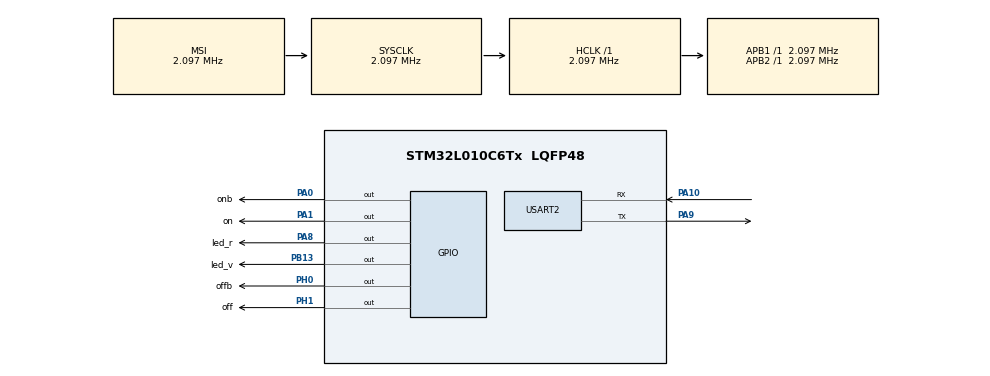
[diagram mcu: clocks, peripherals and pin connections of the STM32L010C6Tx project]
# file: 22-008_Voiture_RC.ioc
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Mcu.Family=STM32L0
Mcu.Name=STM32L010C6Tx
Mcu.Package=LQFP48
PA0.GPIO_Label=onb
PA0.GPIO_PuPd=GPIO_PULLDOWN
PA0.Signal=GPIO_Output
PA1.GPIO_Label=on
PA1.GPIO_PuPd=GPIO_PULLDOWN
PA1.Signal=GPIO_Output
PA10.Mode=Asynchronous
PA10.Signal=USART2_RX
PA8.GPIO_Label=led_r
PA8.PinState=GPIO_PIN_RESET
PA8.Signal=GPIO_Output
PA9.Mode=Asynchronous
PA9.Signal=USART2_TX
PB13.GPIO_Label=led_v
PB13.PinState=GPIO_PIN_RESET
PB13.Signal=GPIO_Output
PH0-OSC_IN.GPIO_Label=offb
PH0-OSC_IN.GPIO_PuPd=GPIO_PULLUP
PH0-OSC_IN.Signal=GPIO_Output
PH1-OSC_OUT.GPIO_Label=off
PH1-OSC_OUT.GPIO_PuPd=GPIO_PULLDOWN
PH1-OSC_OUT.Signal=GPIO_Output
ProjectManager.HeapSize=0x200
ProjectManager.StackSize=0x400
ProjectManager.TargetToolchain=STM32CubeIDE
RCC.AHBFreq_Value=2097000
RCC.APB1Freq_Value=2097000
RCC.APB1TimFreq_Value=2097000
RCC.APB2Freq_Value=2097000
RCC.APB2TimFreq_Value=2097000
RCC.HSE_VALUE=8000000
RCC.HSI16_VALUE=16000000
RCC.HSI_VALUE=16000000
RCC.LSE_VALUE=32768
RCC.MSI_VALUE=2097000
RCC.SYSCLKFreq_VALUE=2097000
RCC.VCOOutputFreq_Value=48000000
USART2.VirtualMode=VM_ASYNC
board=custom

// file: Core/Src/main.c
/* USER CODE BEGIN Header */
/**
  ******************************************************************************
  * @file           : main.c
  * @brief          : Main program body
  ******************************************************************************
  * @attention
  *
  * Copyright (c) 2023 STMicroelectronics.
  * All rights reserved.
  *
  * This software is licensed under terms that can be found in the LICENSE file
  * in the root directory of this software component.
  * If no LICENSE file comes with this software, it is provided AS-IS.
  *
  ******************************************************************************
  */
/* USER CODE END Header */
#include "main.h"

/* USER CODE BEGIN Includes */
#include "hal.h"
/* USER CODE END Includes */

UART_HandleTypeDef huart2;

void SystemClock_Config(void);
static void MX_GPIO_Init(void);
static void MX_USART2_UART_Init(void);

int main(void)
{

  /* MCU Configuration--------------------------------------------------------*/

  /* Reset of all peripherals, Initializes the Flash interface and the Systick. */
  HAL_Init();

  /* Configure the system clock */
  SystemClock_Config();

  /* Initialize all configured peripherals */
  MX_GPIO_Init();
  MX_USART2_UART_Init();

  /* Infinite loop */
  /* USER CODE BEGIN WHILE */
  uint32_t time_U32 = HAL_millis_U32();
  const uint32_t timeout_ms_U32 = 500;
  bool flag_led_B = false;
  while (1)
  {
	  /*if (HAL_millis_U32()-time_U32>timeout_ms_U32)
	  {
		  HAL_setLed(LED_ROUGE_EN, flag_led_B);
		  flag_led_B = 1-flag_led_B;
		  time_U32 = HAL_millis_U32();
	  }*/
	  HAL_GPIO_WritePin(GPIOH, offb_Pin, GPIO_PIN_SET);
	  HAL_GPIO_WritePin(GPIOH, off_Pin, GPIO_PIN_SET);
	  HAL_GPIO_WritePin(GPIOA, onb_Pin, GPIO_PIN_RESET);
	  HAL_GPIO_WritePin(GPIOA, on_Pin, GPIO_PIN_RESET);

    /* USER CODE END WHILE */

  }
}

void SystemClock_Config(void)
{
  RCC_OscInitTypeDef RCC_OscInitStruct = {0};
  RCC_ClkInitTypeDef RCC_ClkInitStruct = {0};
  RCC_PeriphCLKInitTypeDef PeriphClkInit = {0};

  /** Configure the main internal regulator output voltage
  */
  __HAL_PWR_VOLTAGESCALING_CONFIG(PWR_REGULATOR_VOLTAGE_SCALE1);

  /** Initializes the RCC Oscillators according to the specified parameters
  * in the RCC_OscInitTypeDef structure.
  */
  RCC_OscInitStruct.OscillatorType = RCC_OSCILLATORTYPE_MSI;
  RCC_OscInitStruct.MSIState = RCC_MSI_ON;
  RCC_OscInitStruct.MSICalibrationValue = 0;
  RCC_OscInitStruct.MSIClockRange = RCC_MSIRANGE_5;
  RCC_OscInitStruct.PLL.PLLState = RCC_PLL_NONE;
  if (HAL_RCC_OscConfig(&RCC_OscInitStruct) != HAL_OK)
  {
    Error_Handler();
  }

  /** Initializes the CPU, AHB and APB buses clocks
  */
  RCC_ClkInitStruct.ClockType = RCC_CLOCKTYPE_HCLK|RCC_CLOCKTYPE_SYSCLK
                              |RCC_CLOCKTYPE_PCLK1|RCC_CLOCKTYPE_PCLK2;
  RCC_ClkInitStruct.SYSCLKSource = RCC_SYSCLKSOURCE_MSI;
  RCC_ClkInitStruct.AHBCLKDivider = RCC_SYSCLK_DIV1;
  RCC_ClkInitStruct.APB1CLKDivider = RCC_HCLK_DIV1;
  RCC_ClkInitStruct.APB2CLKDivider = RCC_HCLK_DIV1;

  if (HAL_RCC_ClockConfig(&RCC_ClkInitStruct, FLASH_LATENCY_0) != HAL_OK)
  {
    Error_Handler();
  }
  PeriphClkInit.PeriphClockSelection = RCC_PERIPHCLK_USART2;
  PeriphClkInit.Usart2ClockSelection = RCC_USART2CLKSOURCE_PCLK1;
  if (HAL_RCCEx_PeriphCLKConfig(&PeriphClkInit) != HAL_OK)
  {
    Error_Handler();
  }
}

static void MX_USART2_UART_Init(void)
{

  huart2.Instance = USART2;
  huart2.Init.BaudRate = 115200;
  huart2.Init.WordLength = UART_WORDLENGTH_8B;
  huart2.Init.StopBits = UART_STOPBITS_1;
  huart2.Init.Parity = UART_PARITY_NONE;
  huart2.Init.Mode = UART_MODE_TX_RX;
  huart2.Init.HwFlowCtl = UART_HWCONTROL_NONE;
  huart2.Init.OverSampling = UART_OVERSAMPLING_16;
  huart2.Init.OneBitSampling = UART_ONE_BIT_SAMPLE_DISABLE;
  huart2.AdvancedInit.AdvFeatureInit = UART_ADVFEATURE_NO_INIT;
  if (HAL_UART_Init(&huart2) != HAL_OK)
  {
    Error_Handler();
  }

}

static void MX_GPIO_Init(void)
{
  GPIO_InitTypeDef GPIO_InitStruct = {0};

  /* GPIO Ports Clock Enable */
  __HAL_RCC_GPIOH_CLK_ENABLE();
  __HAL_RCC_GPIOA_CLK_ENABLE();
  __HAL_RCC_GPIOB_CLK_ENABLE();

  /*Configure GPIO pin Output Level */
  HAL_GPIO_WritePin(GPIOH, offb_Pin|off_Pin, GPIO_PIN_RESET);

  /*Configure GPIO pin Output Level */
  HAL_GPIO_WritePin(GPIOA, onb_Pin|on_Pin|led_r_Pin, GPIO_PIN_RESET);

  /*Configure GPIO pin Output Level */
  HAL_GPIO_WritePin(led_v_GPIO_Port, led_v_Pin, GPIO_PIN_RESET);

  /*Configure GPIO pin : offb_Pin */
  GPIO_InitStruct.Pin = offb_Pin;
  GPIO_InitStruct.Mode = GPIO_MODE_OUTPUT_PP;
  GPIO_InitStruct.Pull = GPIO_PULLUP;
  GPIO_InitStruct.Speed = GPIO_SPEED_FREQ_LOW;
  HAL_GPIO_Init(offb_GPIO_Port, &GPIO_InitStruct);

  /*Configure GPIO pin : off_Pin */
  GPIO_InitStruct.Pin = off_Pin;
  GPIO_InitStruct.Mode = GPIO_MODE_OUTPUT_PP;
  GPIO_InitStruct.Pull = GPIO_PULLDOWN;
  GPIO_InitStruct.Speed = GPIO_SPEED_FREQ_LOW;
  HAL_GPIO_Init(off_GPIO_Port, &GPIO_InitStruct);

  /*Configure GPIO pins : onb_Pin on_Pin */
  GPIO_InitStruct.Pin = onb_Pin|on_Pin;
  GPIO_InitStruct.Mode = GPIO_MODE_OUTPUT_PP;
  GPIO_InitStruct.Pull = GPIO_PULLDOWN;
  GPIO_InitStruct.Speed = GPIO_SPEED_FREQ_LOW;
  HAL_GPIO_Init(GPIOA, &GPIO_InitStruct);

  /*Configure GPIO pin : led_v_Pin */
  GPIO_InitStruct.Pin = led_v_Pin;
  GPIO_InitStruct.Mode = GPIO_MODE_OUTPUT_PP;
  GPIO_InitStruct.Pull = GPIO_NOPULL;
  GPIO_InitStruct.Speed = GPIO_SPEED_FREQ_LOW;
  HAL_GPIO_Init(led_v_GPIO_Port, &GPIO_InitStruct);

  /*Configure GPIO pin : led_r_Pin */
  GPIO_InitStruct.Pin = led_r_Pin;
  GPIO_InitStruct.Mode = GPIO_MODE_OUTPUT_PP;
  GPIO_InitStruct.Pull = GPIO_NOPULL;
  GPIO_InitStruct.Speed = GPIO_SPEED_FREQ_LOW;
  HAL_GPIO_Init(led_r_GPIO_Port, &GPIO_InitStruct);

}

void Error_Handler(void)
{
  __disable_irq();
  while (1)
  {
  }
}
